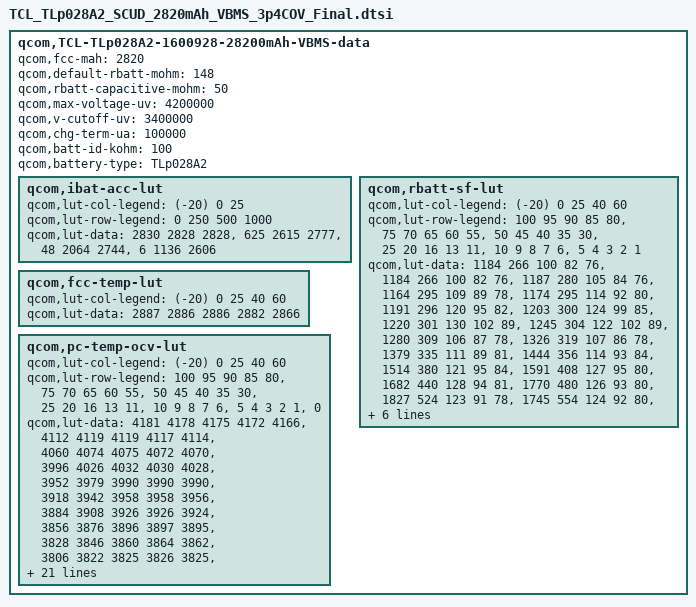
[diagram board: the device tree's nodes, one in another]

 qcom,TCL-TLp028A2-1600928-28200mAh-VBMS-data {
	qcom,fcc-mah = <2820>;
	qcom,default-rbatt-mohm = <148>;
	qcom,rbatt-capacitive-mohm = <50>;
	qcom,max-voltage-uv = <4200000>;
	qcom,v-cutoff-uv = <3400000>;
	qcom,chg-term-ua = <100000>;
	qcom,batt-id-kohm = <100>;
    qcom,battery-type = "TLp028A2";

	qcom,ibat-acc-lut {
		qcom,lut-col-legend = <(-20) 0 25>;
		qcom,lut-row-legend = <0 250 500 1000>;
		qcom,lut-data = <2830 2828 2828>,
				<625 2615 2777>,
				<48 2064 2744>,
				<6 1136 2606>;
	};

	qcom,rbatt-sf-lut {
		qcom,lut-col-legend = <(-20) 0 25 40 60>;
		qcom,lut-row-legend = <100 95 90 85 80>,
				<75 70 65 60 55>,
				<50 45 40 35 30>,
				<25 20 16 13 11>,
				<10 9 8 7 6>,
				<5 4 3 2 1>;
		qcom,lut-data = <1184 266 100 82 76>,
				<1184 266 100 82 76>,
				<1187 280 105 84 76>,
				<1164 295 109 89 78>,
				<1174 295 114 92 80>,
				<1191 296 120 95 82>,
				<1203 300 124 99 85>,
				<1220 301 130 102 89>,
				<1245 304 122 102 89>,
				<1280 309 106 87 78>,
				<1326 319 107 86 78>,
				<1379 335 111 89 81>,
				<1444 356 114 93 84>,
				<1514 380 121 95 84>,
				<1591 408 127 95 80>,
				<1682 440 128 94 81>,
				<1770 480 126 93 80>,
				<1827 524 123 91 78>,
				<1745 554 124 92 80>,
				<1651 543 131 97 82>,
				<1683 559 135 100 83>,
				<1726 578 139 102 85>,
				<1845 603 146 104 85>,
				<2007 628 149 105 84>,
				<2203 653 147 99 82>,
				<2474 684 145 99 84>,
				<2854 718 150 103 85>,
				<3448 769 158 108 90>,
				<4532 843 175 116 97>,
				<7376 1068 241 161 124>;
	};

	qcom,fcc-temp-lut {
		qcom,lut-col-legend = <(-20) 0 25 40 60>;
		qcom,lut-data = <2887 2886 2886 2882 2866>;
	};

	qcom,pc-temp-ocv-lut {
		qcom,lut-col-legend = <(-20) 0 25 40 60>;
		qcom,lut-row-legend = <100 95 90 85 80>,
				<75 70 65 60 55>,
				<50 45 40 35 30>,
				<25 20 16 13 11>,
				<10 9 8 7 6>,
				<5 4 3 2 1>,
				<0>;
		qcom,lut-data = <4181 4178 4175 4172 4166>,
				<4112 4119 4119 4117 4114>,
				<4060 4074 4075 4072 4070>,
				<3996 4026 4032 4030 4028>,
				<3952 3979 3990 3990 3990>,
				<3918 3942 3958 3958 3956>,
				<3884 3908 3926 3926 3924>,
				<3856 3876 3896 3897 3895>,
				<3828 3846 3860 3864 3862>,
				<3806 3822 3825 3826 3825>,
				<3786 3801 3806 3806 3806>,
				<3768 3786 3790 3791 3790>,
				<3752 3773 3779 3778 3777>,
				<3737 3762 3770 3767 3764>,
				<3722 3750 3762 3757 3748>,
				<3706 3736 3748 3740 3728>,
				<3686 3720 3724 3716 3704>,
				<3666 3705 3694 3686 3676>,
				<3647 3691 3682 3674 3664>,
				<3634 3682 3679 3672 3662>,
				<3626 3676 3677 3670 3660>,
				<3614 3671 3674 3668 3658>,
				<3602 3664 3670 3664 3652>,
				<3586 3652 3662 3656 3640>,
				<3568 3634 3642 3633 3611>,
				<3545 3606 3603 3590 3570>,
				<3512 3562 3550 3540 3518>,
				<3466 3504 3484 3474 3452>,
				<3398 3422 3394 3389 3364>,
				<3280 3288 3260 3248 3232>,
				<3000 3000 3000 3000 3000>;
	};
};
